# XMC4300 register map
Vendor: Infineon; File version: 0.5.1 (Superset device XMC4800)
CPU: CM4 r2p0, little endian, MPU, FPU, 6 interrupt priority bits
Registers are 32-bit, read-write, reset 0x0 unless marked. A register's access mark holds for its fields unless they carry their own. Offsets are from the block's base; [hi:lo] are bit positions; {n}, {i} and the like mark numbered series; 'fields as' and 'values as' point back to an identical list.

## GPDMA0 — General Purpose DMA Unit 0
Base 0x500142C0
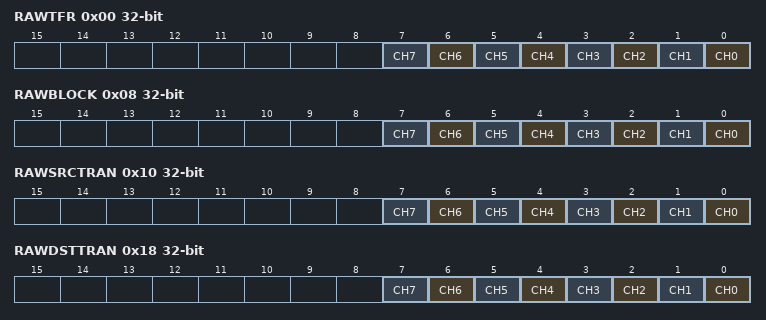
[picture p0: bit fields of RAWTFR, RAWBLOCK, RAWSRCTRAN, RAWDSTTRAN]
0x00 RAWTFR — Raw IntTfr Status
  [n] CH{n} (n=0..7) — Raw Interrupt Status for channel {n}
0x08 RAWBLOCK — Raw IntBlock Status
  [n] CH{n} (n=0..7) — Raw Interrupt Status for channel {n}
0x10 RAWSRCTRAN — Raw IntSrcTran Status
  [n] CH{n} (n=0..7) — Raw Interrupt Status for channel {n}
0x18 RAWDSTTRAN — Raw IntBlock Status
  [n] CH{n} (n=0..7) — Raw Interrupt Status for channel {n}
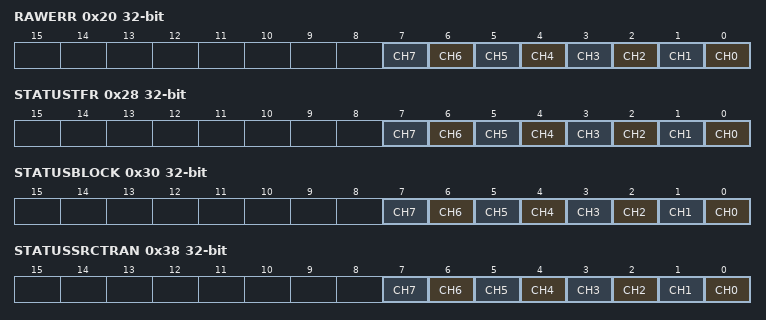
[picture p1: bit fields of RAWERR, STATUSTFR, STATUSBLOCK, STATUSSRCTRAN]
0x20 RAWERR — Raw IntErr Status
  [n] CH{n} (n=0..7) — Raw Interrupt Status for channel {n}
0x28 STATUSTFR ro — IntTfr Status
  [n] CH{n} (n=0..7) — Interrupt Status for channel {n}
0x30 STATUSBLOCK ro — IntBlock Status
  [n] CH{n} (n=0..7) — Interrupt Status for channel {n}
0x38 STATUSSRCTRAN ro — IntSrcTran Status
  [n] CH{n} (n=0..7) — Interrupt Status for channel {n}
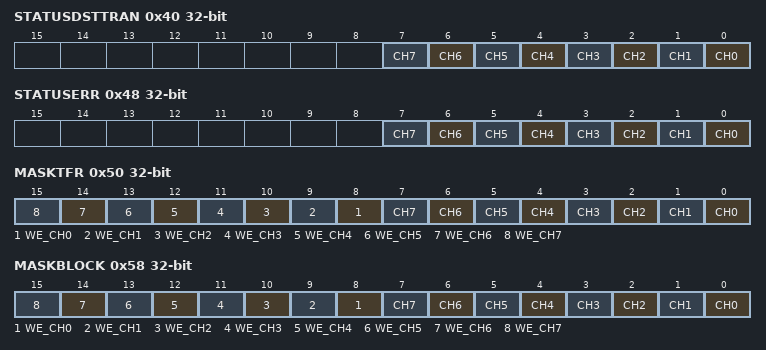
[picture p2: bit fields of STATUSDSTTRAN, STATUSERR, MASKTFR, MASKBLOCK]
0x40 STATUSDSTTRAN ro — IntBlock Status
  [n] CH{n} (n=0..7) — Interrupt Status for channel {n}
0x48 STATUSERR ro — IntErr Status
  [n] CH{n} (n=0..7) — Interrupt Status for channel {n}
0x50 MASKTFR access per field — Mask for Raw IntTfr Status
  [n+8] WE_CH{n} wo (n=0..7) — Write enable for mask bit of channel {n}
    0=write disabled; 1=write enabled
  [n] CH{n} rw (n=0..7) — Mask bit for channel {n}
    0=masked; 1=unmasked
0x58 MASKBLOCK access per field — Mask for Raw IntBlock Status
  fields as MASKTFR
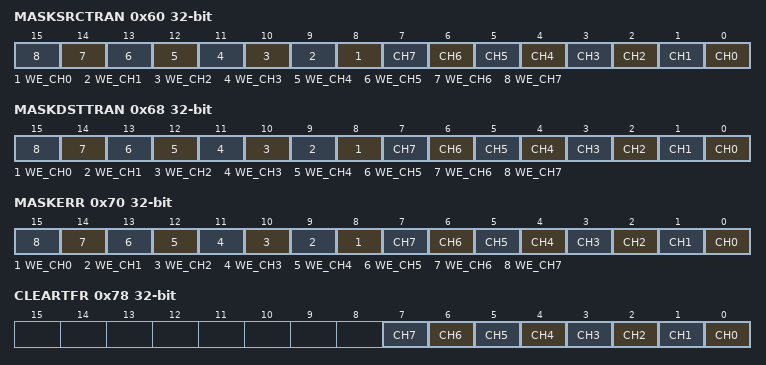
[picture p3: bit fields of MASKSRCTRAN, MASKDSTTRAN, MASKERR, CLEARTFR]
0x60 MASKSRCTRAN access per field — Mask for Raw IntSrcTran Status
  fields as MASKTFR
0x68 MASKDSTTRAN access per field — Mask for Raw IntBlock Status
  fields as MASKTFR
0x70 MASKERR access per field — Mask for Raw IntErr Status
  fields as MASKTFR
0x78 CLEARTFR wo — IntTfr Status
  [all] fields
    0=no effect; 1=clear status
  [n] CH{n} (n=0..7) — Clear Interrupt Status and Raw Status for channel {n}
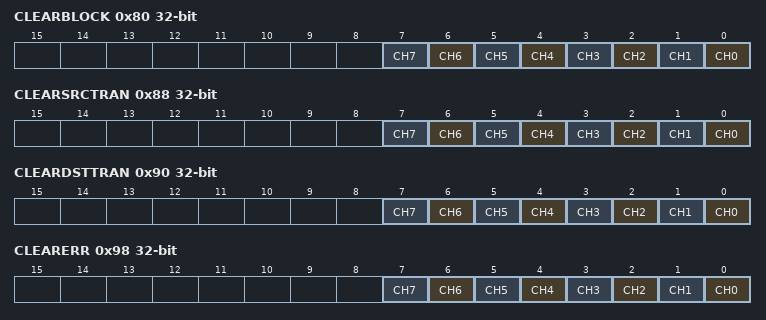
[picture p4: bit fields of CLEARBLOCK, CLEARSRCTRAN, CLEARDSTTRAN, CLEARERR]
0x80 CLEARBLOCK wo — IntBlock Status
  fields as CLEARTFR
0x88 CLEARSRCTRAN wo — IntSrcTran Status
  fields as CLEARTFR
0x90 CLEARDSTTRAN wo — IntBlock Status
  fields as CLEARTFR
0x98 CLEARERR wo — IntErr Status
  fields as CLEARTFR
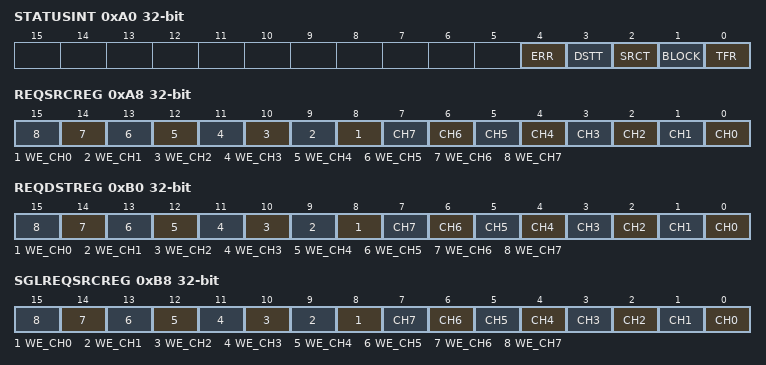
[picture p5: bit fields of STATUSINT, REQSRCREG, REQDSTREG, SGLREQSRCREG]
0xA0 STATUSINT ro — Combined Interrupt Status Register
  [4] ERR — OR of the contents of STATUSERR register
  [3] DSTT — OR of the contents of STATUSDSTTRAN register
  [2] SRCT — OR of the contents of STATUSSRCTRAN register
  [1] BLOCK — OR of the contents of STATUSBLOCK register
  [0] TFR — OR of the contents of STATUSTFR register
0xA8 REQSRCREG access per field — Source Software Transaction Request Register
  [n+8] WE_CH{n} wo (n=0..7) — Source request write enable for channel {n}
    0=write disabled; 1=write enabled
  [n] CH{n} rw (n=0..7) — Source request for channel {n}
0xB0 REQDSTREG access per field — Destination Software Transaction Request Register
  fields as REQSRCREG
0xB8 SGLREQSRCREG access per field — Single Source Transaction Request Register
  fields as REQSRCREG
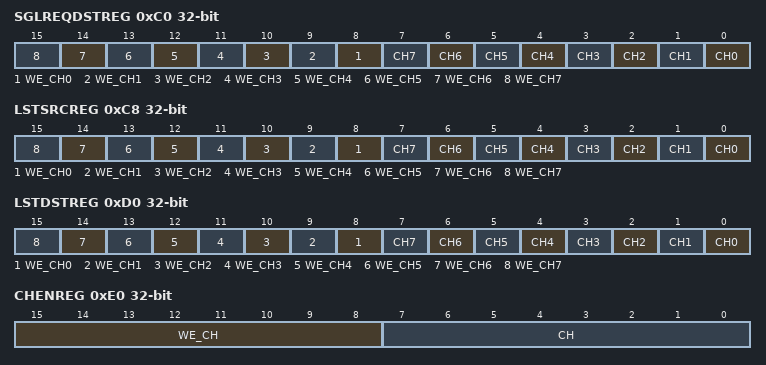
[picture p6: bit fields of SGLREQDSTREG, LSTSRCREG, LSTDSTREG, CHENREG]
0xC0 SGLREQDSTREG access per field — Single Destination Transaction Request Register
  fields as REQSRCREG
0xC8 LSTSRCREG access per field — Last Source Transaction Request Register
  [n+8] WE_CH{n} wo (n=0..7) — Source last transaction request write enable for channel {n}
    0=write disabled; 1=write enabled
  [n] CH{n} rw (n=0..7) — Source last request for channel {n}
    0=Not last transaction in current block; 1=Last transaction in current block
0xD0 LSTDSTREG access per field — Last Destination Transaction Request Register
  [n+8] WE_CH{n} wo (n=0..7) — Destination last transaction request write enable for channel {n}
    0=write disabled; 1=write enabled
  [n] CH{n} rw (n=0..7) — Destination last request for channel {n}
    values as LSTSRCREG.CH0
0xD8 DMACFGREG — GPDMA Configuration Register
  [0] DMA_EN — GPDMA Enable bit.
    0=GPDMA Disabled; 1=GPDMA Enabled
0xE0 CHENREG access per field — GPDMA Channel Enable Register
  [15:8] WE_CH wo — Channel enable write enable
  [7:0] CH rw — Enables/Disables the channel
    0=Disable the Channel; 1=Enable the Channel
0xE8 ID ro reset 0xAFC000 (reset mask 0xFFFFFF00) — GPDMA0 ID Register
  [31:0] VALUE — Hardcoded GPDMA Peripheral ID
0x138 TYPE ro reset 0x44571110 — GPDMA Component Type
  [31:0] VALUE — Component Type
0x13C VERSION ro reset 0x3231342A — DMA Component Version
  [31:0] VALUE — Version number of the component
